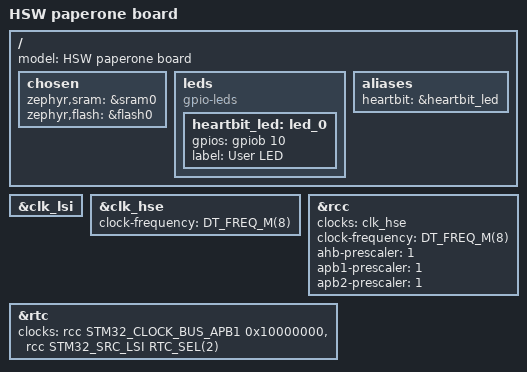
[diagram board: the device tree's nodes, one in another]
/*
 * Copyright (c) 2024 STMicroelectronics
 *
 * SPDX-License-Identifier: Apache-2.0
 */

/dts-v1/;
#include <st/f4/stm32f413Xg.dtsi>
#include <st/f4/stm32f413v(g-h)tx-pinctrl.dtsi>
#include "arduino_r3_connector.dtsi"
#include <zephyr/dt-bindings/input/input-event-codes.h>

/ {
	model = "HSW paperone board";
	//compatible = "st,stm32f413";

	chosen {
		//zephyr,console = &usart1;
		//zephyr,shell-uart = &usart1;
		zephyr,sram = &sram0;
		zephyr,flash = &flash0;
	};

	leds {
		compatible = "gpio-leds";
		heartbit_led: led_0 {
			gpios = <&gpiob 10 GPIO_ACTIVE_HIGH>;
			label = "User LED";
		};
	};

	aliases {
		heartbit = &heartbit_led;
	};
};

&clk_lsi {
	status = "okay";
};

&clk_hse {
	//hse-bypass;
	clock-frequency = <DT_FREQ_M(8)>; /* STLink 8MHz clock */
	status = "okay";
};


/*
&pll {
	div-m = <4>;
	mul-n = <100>;
	div-p = <2>;
	div-q = <8>;
	clocks = <&clk_hse>;
	status = "okay";
};
*/

&rcc {
	//clocks = <&pll>;
	clocks = <&clk_hse>;
	//clock-frequency = <DT_FREQ_M(100)>;
	clock-frequency = <DT_FREQ_M(8)>;
	ahb-prescaler = <1>;
	apb1-prescaler = <1>;
	apb2-prescaler = <1>;
};

/*
&usart1 {
	pinctrl-0 = <&usart1_tx_pa9 &usart1_rx_pa10>;
	pinctrl-names = "default";
	current-speed = <115200>;
	status = "okay";
};

&usart6 {
	pinctrl-0 = <&usart6_tx_pg14 &usart6_rx_pg9>;
	pinctrl-names = "default";
	current-speed = <115200>;
	status = "okay";
};

&uart7 {
	pinctrl-0 = <&uart7_tx_pf7 &uart7_rx_pf6>;
	pinctrl-names = "default";
	current-speed = <115200>;
	status = "okay";
};

&i2c2 {
	pinctrl-0 = <&i2c2_scl_pb10 &i2c2_sda_pb11>;
	pinctrl-names = "default";
	clock-frequency = <I2C_BITRATE_FAST>;
	status = "okay";
};

&spi3 {
	pinctrl-0 = <&spi3_nss_pa15 &spi3_sck_pb12
		     &spi3_miso_pb4 &spi3_mosi_pb5>;
	pinctrl-names = "default";
	status = "okay";
};
*/

&rtc {
	clocks = <&rcc STM32_CLOCK_BUS_APB1 0x10000000>,
		 <&rcc STM32_SRC_LSI RTC_SEL(2)>;
	status = "okay";
};
